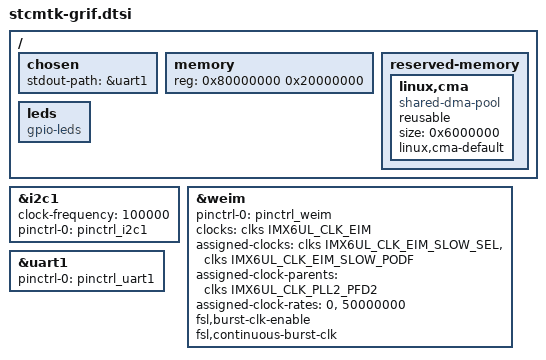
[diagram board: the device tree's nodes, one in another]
/dts-v1/;

#include <dt-bindings/input/input.h>
#include "imx6ull.dtsi"

/ {
	chosen {
		stdout-path = &uart1;
	};

	memory {
		reg = <0x80000000 0x20000000>;
	};

	reserved-memory {
		#address-cells = <1>;
		#size-cells = <1>;
		ranges;

		linux,cma {
			compatible = "shared-dma-pool";
			reusable;
			size = <0x6000000>;
			linux,cma-default;
		};
	};

	leds {
		compatible = "gpio-leds";
	};
};

/* Host side bus */
&i2c1 {
	clock-frequency = <100000>;
	pinctrl-names = "default";
	pinctrl-0 = <&pinctrl_i2c1>;
	status = "okay";
};

&weim {
	pinctrl-names = "default";
	pinctrl-0 = <&pinctrl_weim>;
	/* Open EIM clock gate */
	clocks = <&clks IMX6UL_CLK_EIM>;
	assigned-clocks = <&clks IMX6UL_CLK_EIM_SLOW_SEL>,
			  <&clks IMX6UL_CLK_EIM_SLOW_PODF>;
	/* Choose PLL2 PFD2 clock source 400 MHz... */
	assigned-clock-parents = <&clks IMX6UL_CLK_PLL2_PFD2>;
	/* ... and divide it by 8 */
	assigned-clock-rates = <0>, <50000000>;
	status = "okay";
	#address-cells = <2>;
	#size-cells = <1>;
	ranges = <0 0 0x50000000 0x08000000>; /* We are using only CS0 */
	fsl,burst-clk-enable;
	fsl,continuous-burst-clk;
};

&uart1 {
	pinctrl-names = "default";
	pinctrl-0 = <&pinctrl_uart1>;
	status = "okay";
};
